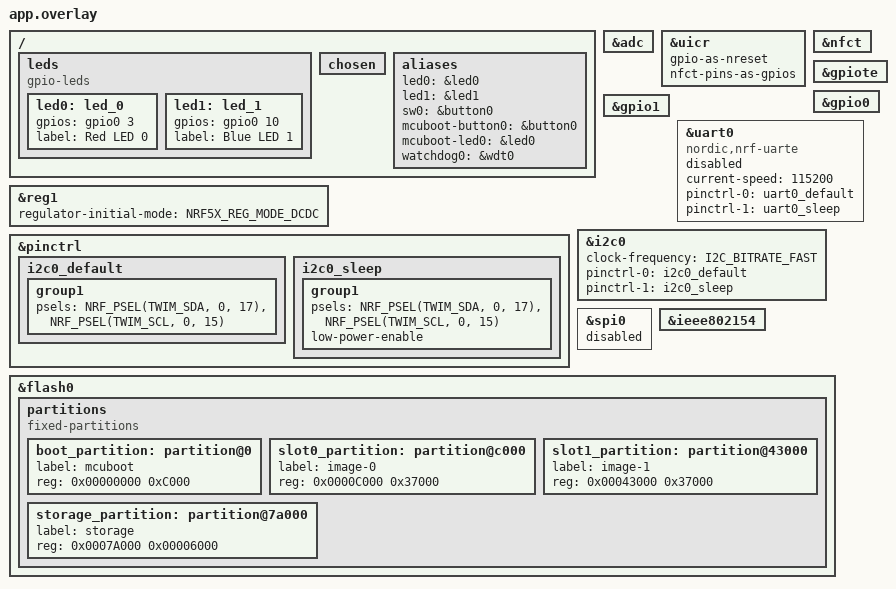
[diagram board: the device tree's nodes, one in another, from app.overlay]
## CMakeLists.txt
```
#
# Copyright (c) 2018 Nordic Semiconductor
#
# SPDX-License-Identifier: LicenseRef-Nordic-5-Clause
#
cmake_minimum_required(VERSION 3.20.0)

find_package(Zephyr REQUIRED HINTS $ENV{ZEPHYR_BASE})
project(peripheral_uart)

# NORDIC SDK APP START
target_sources(app PRIVATE
  src/main.c
  src/ble_conf/ble.c
  src/ble_services/custom_service.c
  src/drv/uart.c
  src/drv/gpio.c
  src/drv/i2c_drv.c
  src/sensor/M117Z/m117_mts01_i2c.c
)

target_include_directories(app PRIVATE 
  ./src
  ./src/ble_conf
  ./src/ble_services
  ./src/drv
  ./src/dfu
  ./src/flash
  ./src/sensor/M117Z
)
# NORDIC SDK APP END
```

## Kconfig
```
#
# Copyright (c) 2018 Nordic Semiconductor
#
# SPDX-License-Identifier: LicenseRef-Nordic-5-Clause
#

source "Kconfig.zephyr"

menu "Nordic UART BLE GATT service sample"

config BT_CUSTOM_SRV_THREAD_STACK_SIZE
	int "Thread stack size"
	default 1024
	help
	  Stack size used in each of the two threads

config BT_CUSTOM_SRV_UART_BUFFER_SIZE
	int "UART payload buffer element size"
	default 40
	help
	  Size of the payload buffer in each RX and TX FIFO element

config BT_CUSTOM_SRV_SECURITY_ENABLED
	bool "Security"
	default y
	select BT_SMP
	help
	  Enable Bluetooth LE security for the UART service

config BT_CUSTOM_SRV_UART_RX_WAIT_TIME
	int "Timeout for UART RX complete event"
	default 50000
	help
	  Wait for RX complete event time in microseconds

config SETTINGS
	default y

config ZMS
	default y if (SOC_FLASH_NRF_RRAM || SOC_FLASH_NRF_MRAM)

config NVS
	default y if !(SOC_FLASH_NRF_RRAM || SOC_FLASH_NRF_MRAM)

endmenu
```

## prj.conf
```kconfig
#
# Copyright (c) 2018 Nordic Semiconductor
#
# SPDX-License-Identifier: LicenseRef-Nordic-5-Clause
#

# Enable the UART driver
CONFIG_UART_ASYNC_API=y
CONFIG_NRFX_UARTE=y
CONFIG_SERIAL=y

CONFIG_GPIO=y

# Make sure printk is printing to the UART console
CONFIG_CONSOLE=y
# CONFIG_UART_CONSOLE=y
CONFIG_RTT_CONSOLE=y

CONFIG_HEAP_MEM_POOL_SIZE=2048

####################蓝牙相关#######################################
CONFIG_BT=y
CONFIG_BT_PERIPHERAL=y
CONFIG_BT_DEVICE_NAME="QTCLKJ01"
CONFIG_BT_MAX_CONN=1
CONFIG_BT_MAX_PAIRED=1
# CONFIG_BT_CUSTOM_SRV_MTU

# BT MTU
# 设置MTU大小，建议设置为247以充分利用2.4GHz频段的单包最大载荷
CONFIG_BT_GATT_CLIENT=y
CONFIG_BT_L2CAP_TX_MTU=182
CONFIG_BT_BUF_ACL_TX_SIZE=186
CONFIG_BT_BUF_ACL_RX_SIZE=186

# 功率设置
CONFIG_BT_CTLR_TX_PWR_PLUS_8=y
# CONFIG_BT_CTLR_TX_PWR_PLUS_4=y
# CONFIG_BT_CTLR_TX_PWR_PLUS_0=y
# CONFIG_BT_CTLR_TX_PWR_MINUS_2=y


# Enable the NUS service
# CONFIG_BT_NUS=y
####################蓝牙相关#######################################


# Enable bonding
CONFIG_BT_SETTINGS=y
CONFIG_FLASH=y
CONFIG_FLASH_PAGE_LAYOUT=y
CONFIG_FLASH_MAP=y

# Enable DK LED and Buttons library
CONFIG_DK_LIBRARY=y

CONFIG_SYSTEM_WORKQUEUE_STACK_SIZE=2048
# Config logger
CONFIG_LOG=y
CONFIG_USE_SEGGER_RTT=y
CONFIG_SEGGER_RTT_BUFFER_SIZE_UP=8192
CONFIG_LOG_BACKEND_RTT=y
CONFIG_LOG_BACKEND_UART=n
CONFIG_LOG_PRINTK=n

CONFIG_ASSERT=y

# I2C
CONFIG_I2C=y
# 启用 nrfx TWIM 驱动
CONFIG_NRFX_TWIM=y
```

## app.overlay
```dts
/*
 * Copyright (c) 2022 Nordic Semiconductor ASA
 *
 * SPDX-License-Identifier: LicenseRef-Nordic-5-Clause
 */

/ {
    leds {
		compatible = "gpio-leds";

		led0: led_0 {
			gpios = <&gpio0 3 GPIO_ACTIVE_HIGH>;
			label = "Red LED 0";
		};

		led1: led_1 {
			gpios = <&gpio0 10 GPIO_ACTIVE_HIGH>;
			label = "Blue LED 1";
		};

	};

    chosen {

    };

    aliases {
		led0 = &led0;
		led1 = &led1;
		sw0 = &button0;
		mcuboot-button0 = &button0;
		mcuboot-led0 = &led0;
		watchdog0 = &wdt0;
	};
};


&reg1 {
	regulator-initial-mode = <NRF5X_REG_MODE_DCDC>;
};

&adc {
	status = "okay";
};

&uicr {
	gpio-as-nreset;
	// nfct-pins-as-gpios;
	nfct-pins-as-gpios;
};

&nfct {
	status = "okay";
};

&gpiote {
	status = "okay";
};

&gpio0 {
	status = "okay";
};

&gpio1 {
	status = "okay";
};

&uart0 {
	compatible = "nordic,nrf-uarte";
	// status = "okay" "disabled";
	status = "disabled";
	current-speed = <115200>;
	pinctrl-0 = <&uart0_default>;
	pinctrl-1 = <&uart0_sleep>;
	pinctrl-names = "default", "sleep";
};

/* 重新定义 i2c0_default 和 i2c0_sleep 以覆盖默认引脚 */
&pinctrl {
	/* 覆盖默认的 i2c0_default */
	i2c0_default: i2c0_default {
		group1 {
			psels = <NRF_PSEL(TWIM_SDA, 0, 17)>,    /* P0.26 SDA */
					<NRF_PSEL(TWIM_SCL, 0, 15)>;    /* P0.27 SCL */
		};
	};

	/* 覆盖默认的 i2c0_sleep */
	i2c0_sleep: i2c0_sleep {
		group1 {
			psels = <NRF_PSEL(TWIM_SDA, 0, 17)>,
					<NRF_PSEL(TWIM_SCL, 0, 15)>;
			low-power-enable;
		};
	};
};

/* 确保I2C0总线已启用 */
&i2c0 {
    status = "okay";
	clock-frequency = <I2C_BITRATE_FAST>; //I2C_BITRATE_STANDARD 250000 I2C_BITRATE_FAST
    pinctrl-0 = <&i2c0_default>;
	pinctrl-1 = <&i2c0_sleep>;
	pinctrl-names = "default", "sleep";
};

&spi0 {
	status = "disabled";


};


&ieee802154 {
	status = "okay";
};

&flash0 {
	partitions {
		compatible = "fixed-partitions";
		#address-cells = <1>;
		#size-cells = <1>;

		boot_partition: partition@0 {
			label = "mcuboot";
			reg = <0x00000000 0xC000>;
		};

		slot0_partition: partition@c000 {
			label = "image-0";
			reg = <0x0000C000 0x37000>;
		};

		slot1_partition: partition@43000 {
			label = "image-1";
			reg = <0x00043000 0x37000>;
		};

		storage_partition: partition@7a000 {
			label = "storage";
			reg = <0x0007A000 0x00006000>;
		};
	};
};
```

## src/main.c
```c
// main.c
#include <zephyr/kernel.h>
#include <zephyr/logging/log.h>
#include <dk_buttons_and_leds.h>
#include <zephyr/drivers/i2c.h>

#include "uart.h"
#include "gpio.h"
#include "ble.h"
#include "main.h"

#include "i2c_drv.h"

#include "m117_mts01_i2c.h"

LOG_MODULE_REGISTER(main, LOG_LEVEL_INF);

#define RUN_STATUS_LED DK_LED2
#define RUN_LED_BLINK_INTERVAL 1000

dev_id_t dev_id;
device_mode_t device_mode;

/* 温度采样完成回调 */
static void temp_sample_done(float temp_celsius, bool success, void *user_data)
{
	int tmp = temp_celsius*100;
    if (success) {
        LOG_INF("temperature: %d °C", tmp);
        tempratrue = temp_celsius;

        /* 可以在这里处理后续逻辑，如显示、上报等 */
    } else {
        LOG_ERR("temperature sample failed");
    }
}

static void configure_gpio(void)
{
	int err;

	err = dk_leds_init();
	if (err) {
		LOG_ERR("Cannot init LEDs (err: %d)", err);
	}
}

// MPU6050 测试
void mpu6050_test(void)
{
    uint8_t reg = 0x75;
    uint8_t who_am_i = 0;
    int ret;
    
    // 方式1：分步读写（推荐）
    ret = i2c_read_reg(0, 0x68, reg, &who_am_i, 1);
    if (ret != I2C_OK) {
        LOG_ERR("Write failed: %d", ret);
        return;
    }
    LOG_INF("[I2C_Read] MPU6050 WHO_AM_I = 0x%02X", who_am_i);

}

void error_handler(void)
{
	LOG_ERR("error_handler");
	dk_set_leds_state(DK_ALL_LEDS_MSK, DK_NO_LEDS_MSK);
	while (1) {
		k_sleep(K_MSEC(1000));
	}
}
int main(void)
{
	int ret = 0;
	int blink_status = 0;
	int electric = 0;
	uint8_t status, cfg;
	float temp;

	configure_gpio();
    gpio_init();
    gpio_set(LED_VDD_PORT, LED_VDD_PIN, 1);

	if (ble_init() != 0) {
		error_handler();
	}

	// 初始化 I2C
    i2c_init(0);
	k_sleep(K_MSEC(1000));
	
	//读取温度
	m117_single_sample_async(temp_sample_done, NULL);
    
	/******* 添加其他传感器代码 *******/


	/******* 添加其他传感器代码 *******/
	
    LOG_INF("Enter while(1)");
	k_sleep(K_MSEC(1000));

	for (;;) {
        electric = !electric;
        if(electric == 0){
		    dk_set_led(DK_LED2, (++blink_status) % 2);
		    dk_set_led(DK_LED1, (blink_status) % 2);
        }
		k_sleep(K_MSEC(RUN_LED_BLINK_INTERVAL));

		// mpu6050_test();
		m117_single_sample_async(temp_sample_done, NULL);
	}
	
	return 0;
}
```

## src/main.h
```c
#ifndef _MAIN_H_
#define _MAIN_H_

#define PROJECT_NUM		29
#define FW_VERSION		3
#define HW_VERSION		3

/*! Enum to string converter*/
#ifndef enum_to_string
#define enum_to_string(a)  #a
#endif

/** @brief Device ID 长度 (字节) */
/** @brief Device ID length (bytes) */
#define DEV_ID_LENGTH          14
#define PRO_ID_LENGTH          3

typedef struct{
    char device_id[DEV_ID_LENGTH];
    char product_id[PRO_ID_LENGTH];
} __attribute__((packed)) dev_id_t;

typedef enum{
	MONITOR_MODE,		//监测模式
	LOW_POWER_MODE,		//低功耗模式
	TEST_MODE,			//测试模式
}device_mode_t;

extern dev_id_t dev_id;
extern device_mode_t device_mode;
#endif
```
